VERSION ""

NS_ :

BS_:

BU_: Minieye ADAS

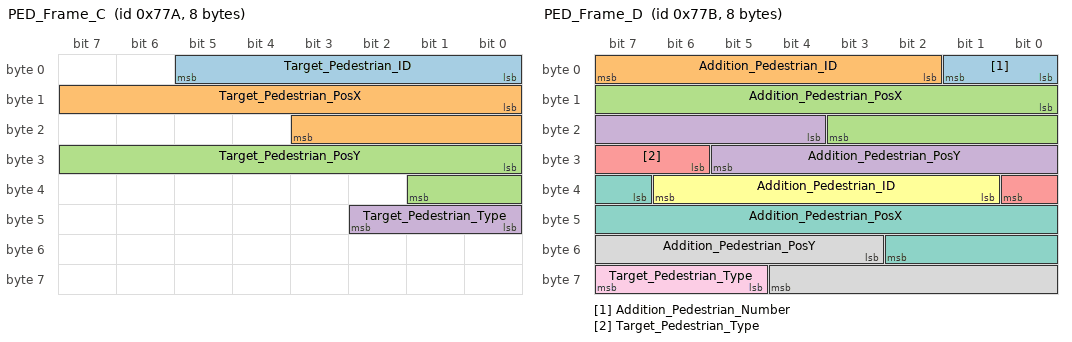
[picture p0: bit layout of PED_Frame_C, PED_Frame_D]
BO_ 1914 PED_Frame_C: 8 MINIEYE_TRANSMITTER
 SG_ Target_Pedestrian_ID : 0|6@1+ (1,0) [0|63] "" Vector__XXX
 SG_ Target_Pedestrian_PosX : 8|12@1+ (0.0625,0) [0|250] "m" Vector__XXX
 SG_ Target_Pedestrian_PosY : 24|10@1- (0.0625,0) [-32|31.9375] "m" Vector__XXX
 SG_ Target_Pedestrian_Type : 40|3@1+ (1,0) [0|7] "" Vector__XXX

BO_ 1915 PED_Frame_D: 8 MINIEYE_TRANSMITTER
 SG_ Addition_Pedestrian_Number : 0|2@1+ (1,0) [0|2] "" Vector__XXX
 SG_ Addition_Pedestrian_ID : 2|6@1+ (1,0) [0|63] "" Vector__XXX
 SG_ Addition_Pedestrian_PosX : 8|12@1+ (0.0625,0) [0|250] "m" Vector__XXX
 SG_ Addition_Pedestrian_PosY : 20|10@1- (0.0625,0) [-32|31.9375] "m" Vector__XXX
 SG_ Target_Pedestrian_Type : 30|3@1+ (1,0) [0|7] "" Vector__XXX
 SG_ Addition_Pedestrian_ID : 33|6@1+ (1,0) [0|63] "" Vector__XXX
 SG_ Addition_Pedestrian_PosX : 39|12@1+ (0.0625,0) [0|250] "m" Vector__XXX
 SG_ Addition_Pedestrian_PosY : 51|10@1- (0.0625,0) [-32|31.9375] "m" Vector__XXX
 SG_ Target_Pedestrian_Type : 61|3@1+ (1,0) [0|7] "" Vector__XXX

BO_ 1916 PED_Frame_D: 8 MINIEYE_TRANSMITTER
 SG_ Addition_Pedestrian_Number : 0|2@1+ (1,0) [0|2] "" Vector__XXX
 SG_ Addition_Pedestrian_ID : 2|6@1+ (1,0) [0|63] "" Vector__XXX
 SG_ Addition_Pedestrian_PosX : 8|12@1+ (0.0625,0) [0|250] "m" Vector__XXX
 SG_ Addition_Pedestrian_PosY : 20|10@1- (0.0625,0) [-32|31.9375] "m" Vector__XXX
 SG_ Target_Pedestrian_Type : 30|3@1+ (1,0) [0|7] "" Vector__XXX
 SG_ Addition_Pedestrian_ID : 33|6@1+ (1,0) [0|63] "" Vector__XXX
 SG_ Addition_Pedestrian_PosX : 39|12@1+ (0.0625,0) [0|250] "m" Vector__XXX
 SG_ Addition_Pedestrian_PosY : 51|10@1- (0.0625,0) [-32|31.9375] "m" Vector__XXX
 SG_ Target_Pedestrian_Type : 61|3@1+ (1,0) [0|7] "" Vector__XXX

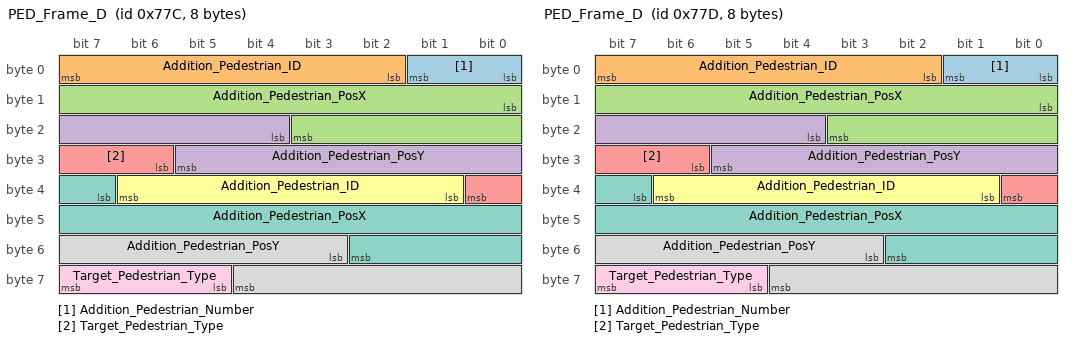
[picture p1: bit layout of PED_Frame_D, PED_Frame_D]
BO_ 1917 PED_Frame_D: 8 MINIEYE_TRANSMITTER
 SG_ Addition_Pedestrian_Number : 0|2@1+ (1,0) [0|2] "" Vector__XXX
 SG_ Addition_Pedestrian_ID : 2|6@1+ (1,0) [0|63] "" Vector__XXX
 SG_ Addition_Pedestrian_PosX : 8|12@1+ (0.0625,0) [0|250] "m" Vector__XXX
 SG_ Addition_Pedestrian_PosY : 20|10@1- (0.0625,0) [-32|31.9375] "m" Vector__XXX
 SG_ Target_Pedestrian_Type : 30|3@1+ (1,0) [0|7] "" Vector__XXX
 SG_ Addition_Pedestrian_ID : 33|6@1+ (1,0) [0|63] "" Vector__XXX
 SG_ Addition_Pedestrian_PosX : 39|12@1+ (0.0625,0) [0|250] "m" Vector__XXX
 SG_ Addition_Pedestrian_PosY : 51|10@1- (0.0625,0) [-32|31.9375] "m" Vector__XXX
 SG_ Target_Pedestrian_Type : 61|3@1+ (1,0) [0|7] "" Vector__XXX

VAL_ 1914 Target_Pedestrian_Type 3 "Pedestrian" 4 "Bicycle" ;
VAL_ 1915 Target_Pedestrian_Type 3 "Pedestrian" 4 "Bicycle" ;
VAL_ 1916 Target_Pedestrian_Type 3 "Pedestrian" 4 "Bicycle" ;
VAL_ 1917 Target_Pedestrian_Type 3 "Pedestrian" 4 "Bicycle" ;
